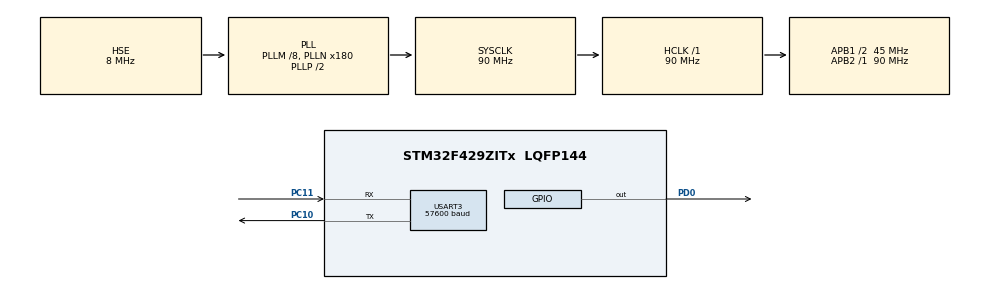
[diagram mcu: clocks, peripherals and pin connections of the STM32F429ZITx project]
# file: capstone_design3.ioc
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Dma.Request0=USART3_RX
Dma.Request1=USART3_TX
Dma.USART3_RX.0.Direction=DMA_PERIPH_TO_MEMORY
Dma.USART3_RX.0.FIFOMode=DMA_FIFOMODE_DISABLE
Dma.USART3_RX.0.Instance=DMA1_Stream1
Dma.USART3_RX.0.MemDataAlignment=DMA_MDATAALIGN_BYTE
Dma.USART3_RX.0.MemInc=DMA_MINC_ENABLE
Dma.USART3_RX.0.Mode=DMA_CIRCULAR
Dma.USART3_RX.0.PeriphDataAlignment=DMA_PDATAALIGN_BYTE
Dma.USART3_RX.0.PeriphInc=DMA_PINC_DISABLE
Dma.USART3_RX.0.Priority=DMA_PRIORITY_LOW
Dma.USART3_TX.1.Direction=DMA_MEMORY_TO_PERIPH
Dma.USART3_TX.1.FIFOMode=DMA_FIFOMODE_DISABLE
Dma.USART3_TX.1.Instance=DMA1_Stream3
Dma.USART3_TX.1.MemDataAlignment=DMA_MDATAALIGN_BYTE
Dma.USART3_TX.1.MemInc=DMA_MINC_ENABLE
Dma.USART3_TX.1.Mode=DMA_NORMAL
Dma.USART3_TX.1.PeriphDataAlignment=DMA_PDATAALIGN_BYTE
Dma.USART3_TX.1.PeriphInc=DMA_PINC_DISABLE
Dma.USART3_TX.1.Priority=DMA_PRIORITY_LOW
Mcu.Family=STM32F4
Mcu.Name=STM32F429ZITx
Mcu.Package=LQFP144
NVIC.DMA1_Stream1_IRQn=true\:0\:0\:false\:false\:true\:false\:true
NVIC.DMA1_Stream3_IRQn=true\:0\:0\:false\:false\:true\:false\:true
NVIC.PriorityGroup=NVIC_PRIORITYGROUP_4
NVIC.TIM3_IRQn=true\:0\:0\:false\:false\:true\:true\:true
NVIC.USART3_IRQn=true\:0\:0\:false\:false\:true\:true\:true
PA13.Mode=Serial_Wire
PA13.Signal=SYS_JTMS-SWDIO
PA14.Mode=Serial_Wire
PA14.Signal=SYS_JTCK-SWCLK
PC10.Mode=Asynchronous
PC10.Signal=USART3_TX
PC11.Mode=Asynchronous
PC11.Signal=USART3_RX
PD0.GPIO_PuPd=GPIO_PULLUP
PD0.GPIO_Speed=GPIO_SPEED_FREQ_HIGH
PD0.Signal=GPIO_Output
PH0/OSC_IN.Mode=HSE-External-Clock-Source
PH0/OSC_IN.Signal=RCC_OSC_IN
PH1/OSC_OUT.Mode=HSE-External-Clock-Source
PH1/OSC_OUT.Signal=RCC_OSC_OUT
ProjectManager.HeapSize=0x200
ProjectManager.StackSize=0x400
ProjectManager.TargetToolchain=STM32CubeIDE
RCC.48MHZClocksFreq_Value=45000000
RCC.AHBFreq_Value=90000000
RCC.APB1CLKDivider=RCC_HCLK_DIV2
RCC.APB1Freq_Value=45000000
RCC.APB1TimFreq_Value=90000000
RCC.APB2Freq_Value=90000000
RCC.APB2TimFreq_Value=90000000
RCC.CortexFreq_Value=90000000
RCC.HCLKFreq_Value=90000000
RCC.HSE_VALUE=8000000
RCC.HSI_VALUE=16000000
RCC.LSE_VALUE=32768
RCC.PLLM=8
RCC.PLLN=180
RCC.PLLSourceVirtual=RCC_PLLSOURCE_HSE
RCC.SYSCLKFreq_VALUE=90000000
RCC.SYSCLKSource=RCC_SYSCLKSOURCE_PLLCLK
RCC.VCOOutputFreq_Value=180000000
TIM3.CounterMode=TIM_COUNTERMODE_CENTERALIGNED2
TIM3.Period=999
TIM3.Prescaler=8999
USART3.BaudRate=57600
USART3.VirtualMode=VM_ASYNC
VP_TIM3_VS_ClockSourceINT.Mode=Internal
board=custom

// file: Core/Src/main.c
/* USER CODE BEGIN Header */
/**
  ******************************************************************************
  * @file           : main.c
  * @brief          : Main program body
  ******************************************************************************
  * @attention
  *
  * <h2><center>&copy; Copyright (c) 2022 STMicroelectronics.
  * All rights reserved.</center></h2>
  *
  * This software component is licensed by ST under BSD 3-Clause license,
  * the "License"; You may not use this file except in compliance with the
  * License. You may obtain a copy of the License at:
  *                        opensource.org/licenses/BSD-3-Clause
  *
  ******************************************************************************
  */
/* USER CODE END Header */
#include "main.h"

TIM_HandleTypeDef htim3;

UART_HandleTypeDef huart3;
DMA_HandleTypeDef hdma_usart3_rx;
DMA_HandleTypeDef hdma_usart3_tx;

/* USER CODE BEGIN PV */
//아두이노 millis 대체 변수
int millis=0;
/* USER CODE END PV */

void SystemClock_Config(void);
static void MX_GPIO_Init(void);
static void MX_DMA_Init(void);
static void MX_USART3_UART_Init(void);
static void MX_TIM3_Init(void);
/* USER CODE BEGIN PFP */
void LED_OnOff(int, int);
/* USER CODE END PFP */

int main(void)
{

  /* MCU Configuration--------------------------------------------------------*/

  /* Reset of all peripherals, Initializes the Flash interface and the Systick. */
  HAL_Init();

  /* Configure the system clock */
  SystemClock_Config();

  /* Initialize all configured peripherals */
  MX_GPIO_Init();
  MX_DMA_Init();
  MX_USART3_UART_Init();
  MX_TIM3_Init();
  /* USER CODE BEGIN 2 */

  HAL_TIM_Base_Start_IT(&htim3);

  LED_OnOff(GPIO_PIN_LedAll, 500);

  /* USER CODE END 2 */

  /* Infinite loop */
  /* USER CODE BEGIN WHILE */
  while (1)
  {

	  loop();
    /* USER CODE END WHILE */

  }
}

void SystemClock_Config(void)
{
  RCC_OscInitTypeDef RCC_OscInitStruct = {0};
  RCC_ClkInitTypeDef RCC_ClkInitStruct = {0};

  /** Configure the main internal regulator output voltage
  */
  __HAL_RCC_PWR_CLK_ENABLE();
  __HAL_PWR_VOLTAGESCALING_CONFIG(PWR_REGULATOR_VOLTAGE_SCALE3);
  /** Initializes the RCC Oscillators according to the specified parameters
  * in the RCC_OscInitTypeDef structure.
  */
  RCC_OscInitStruct.OscillatorType = RCC_OSCILLATORTYPE_HSE;
  RCC_OscInitStruct.HSEState = RCC_HSE_BYPASS;
  RCC_OscInitStruct.PLL.PLLState = RCC_PLL_ON;
  RCC_OscInitStruct.PLL.PLLSource = RCC_PLLSOURCE_HSE;
  RCC_OscInitStruct.PLL.PLLM = 8;
  RCC_OscInitStruct.PLL.PLLN = 180;
  RCC_OscInitStruct.PLL.PLLP = RCC_PLLP_DIV2;
  RCC_OscInitStruct.PLL.PLLQ = 4;
  if (HAL_RCC_OscConfig(&RCC_OscInitStruct) != HAL_OK)
  {
    Error_Handler();
  }
  /** Activate the Over-Drive mode
  */
  if (HAL_PWREx_EnableOverDrive() != HAL_OK)
  {
    Error_Handler();
  }
  /** Initializes the CPU, AHB and APB buses clocks
  */
  RCC_ClkInitStruct.ClockType = RCC_CLOCKTYPE_HCLK|RCC_CLOCKTYPE_SYSCLK
                              |RCC_CLOCKTYPE_PCLK1|RCC_CLOCKTYPE_PCLK2;
  RCC_ClkInitStruct.SYSCLKSource = RCC_SYSCLKSOURCE_PLLCLK;
  RCC_ClkInitStruct.AHBCLKDivider = RCC_SYSCLK_DIV1;
  RCC_ClkInitStruct.APB1CLKDivider = RCC_HCLK_DIV2;
  RCC_ClkInitStruct.APB2CLKDivider = RCC_HCLK_DIV1;

  if (HAL_RCC_ClockConfig(&RCC_ClkInitStruct, FLASH_LATENCY_2) != HAL_OK)
  {
    Error_Handler();
  }
}

static void MX_TIM3_Init(void)
{

  TIM_ClockConfigTypeDef sClockSourceConfig = {0};
  TIM_MasterConfigTypeDef sMasterConfig = {0};

  htim3.Instance = TIM3;
  htim3.Init.Prescaler = 8999;
  htim3.Init.CounterMode = TIM_COUNTERMODE_CENTERALIGNED2;
  htim3.Init.Period = 999;
  htim3.Init.ClockDivision = TIM_CLOCKDIVISION_DIV1;
  htim3.Init.AutoReloadPreload = TIM_AUTORELOAD_PRELOAD_DISABLE;
  if (HAL_TIM_Base_Init(&htim3) != HAL_OK)
  {
    Error_Handler();
  }
  sClockSourceConfig.ClockSource = TIM_CLOCKSOURCE_INTERNAL;
  if (HAL_TIM_ConfigClockSource(&htim3, &sClockSourceConfig) != HAL_OK)
  {
    Error_Handler();
  }
  sMasterConfig.MasterOutputTrigger = TIM_TRGO_RESET;
  sMasterConfig.MasterSlaveMode = TIM_MASTERSLAVEMODE_DISABLE;
  if (HAL_TIMEx_MasterConfigSynchronization(&htim3, &sMasterConfig) != HAL_OK)
  {
    Error_Handler();
  }

}

static void MX_USART3_UART_Init(void)
{

  huart3.Instance = USART3;
  huart3.Init.BaudRate = 57600;
  huart3.Init.WordLength = UART_WORDLENGTH_8B;
  huart3.Init.StopBits = UART_STOPBITS_1;
  huart3.Init.Parity = UART_PARITY_NONE;
  huart3.Init.Mode = UART_MODE_TX_RX;
  huart3.Init.HwFlowCtl = UART_HWCONTROL_NONE;
  huart3.Init.OverSampling = UART_OVERSAMPLING_16;
  if (HAL_UART_Init(&huart3) != HAL_OK)
  {
    Error_Handler();
  }

}

static void MX_DMA_Init(void)
{

  /* DMA controller clock enable */
  __HAL_RCC_DMA1_CLK_ENABLE();

  /* DMA interrupt init */
  /* DMA1_Stream1_IRQn interrupt configuration */
  HAL_NVIC_SetPriority(DMA1_Stream1_IRQn, 0, 0);
  HAL_NVIC_EnableIRQ(DMA1_Stream1_IRQn);
  /* DMA1_Stream3_IRQn interrupt configuration */
  HAL_NVIC_SetPriority(DMA1_Stream3_IRQn, 0, 0);
  HAL_NVIC_EnableIRQ(DMA1_Stream3_IRQn);

}

static void MX_GPIO_Init(void)
{
  GPIO_InitTypeDef GPIO_InitStruct = {0};

  /* GPIO Ports Clock Enable */
  __HAL_RCC_GPIOH_CLK_ENABLE();
  __HAL_RCC_GPIOA_CLK_ENABLE();
  __HAL_RCC_GPIOC_CLK_ENABLE();
  __HAL_RCC_GPIOD_CLK_ENABLE();

  /*Configure GPIO pin Output Level */
  HAL_GPIO_WritePin(GPIOD, GPIO_PIN_0, GPIO_PIN_RESET);

  /*Configure GPIO pin : PD0 */
  GPIO_InitStruct.Pin = GPIO_PIN_0;
  GPIO_InitStruct.Mode = GPIO_MODE_OUTPUT_PP;
  GPIO_InitStruct.Pull = GPIO_PULLUP;
  GPIO_InitStruct.Speed = GPIO_SPEED_FREQ_HIGH;
  HAL_GPIO_Init(GPIOD, &GPIO_InitStruct);

}

/* USER CODE BEGIN 4 */

void HAL_TIM_PeriodElapsedCallback(TIM_HandleTypeDef *htim)
{
	millis++;

}

void LED_OnOff(int led, int interval)
{
HAL_GPIO_WritePin(GPIONucleo, led, GPIO_PIN_SET );
HAL_GPIO_WritePin(GPIOExt, led, GPIO_PIN_SET );
HAL_Delay(interval);
HAL_GPIO_WritePin(GPIONucleo, led, GPIO_PIN_RESET );
HAL_GPIO_WritePin(GPIOExt, led, GPIO_PIN_RESET );
}
/* USER CODE END 4 */

void Error_Handler(void)
{
  __disable_irq();
  while (1)
  {
  }
}

/************************ (C) COPYRIGHT STMicroelectronics *****END OF FILE****/
